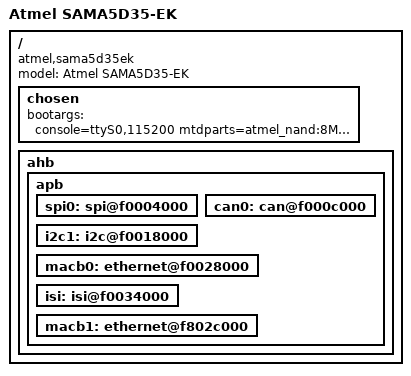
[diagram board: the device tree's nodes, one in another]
/*
 * sama5d35ek.dts - Device Tree file for SAMA5-EK board
 *
 *  Copyright (C) 2012 Atmel,
 *                2012 Ludovic Desroches <ludovic.desroches@atmel.com>
 *
 * Licensed under GPLv2 or later.
 */
/dts-v1/;
/include/ "sama5d3mb.dtsi"

/ {
	model = "Atmel SAMA5D35-EK";
	compatible = "atmel,sama5d35ek", "atmel,sama5ek", "atmel,sama5d3", "atmel,sama5";

	chosen {
		bootargs = "console=ttyS0,115200 mtdparts=atmel_nand:8M(bootstrap/uboot/kernel)ro,-(rootfs) rw rootfstype=ubifs ubi.mtd=1 root=ubi0:rootfs";
	};

	ahb {
		apb {
			spi0: spi@f0004000 {
				status = "okay";
			};

			can0: can@f000c000 {
				status = "okay";
			};

			i2c1: i2c@f0018000 {
				status = "okay";
			};

			macb0: ethernet@f0028000 {
				status = "okay";
			};

			isi: isi@f0034000 {
				status = "okay";
			};

			macb1: ethernet@f802c000 {
				status = "okay";
			};
		};
	};
};
